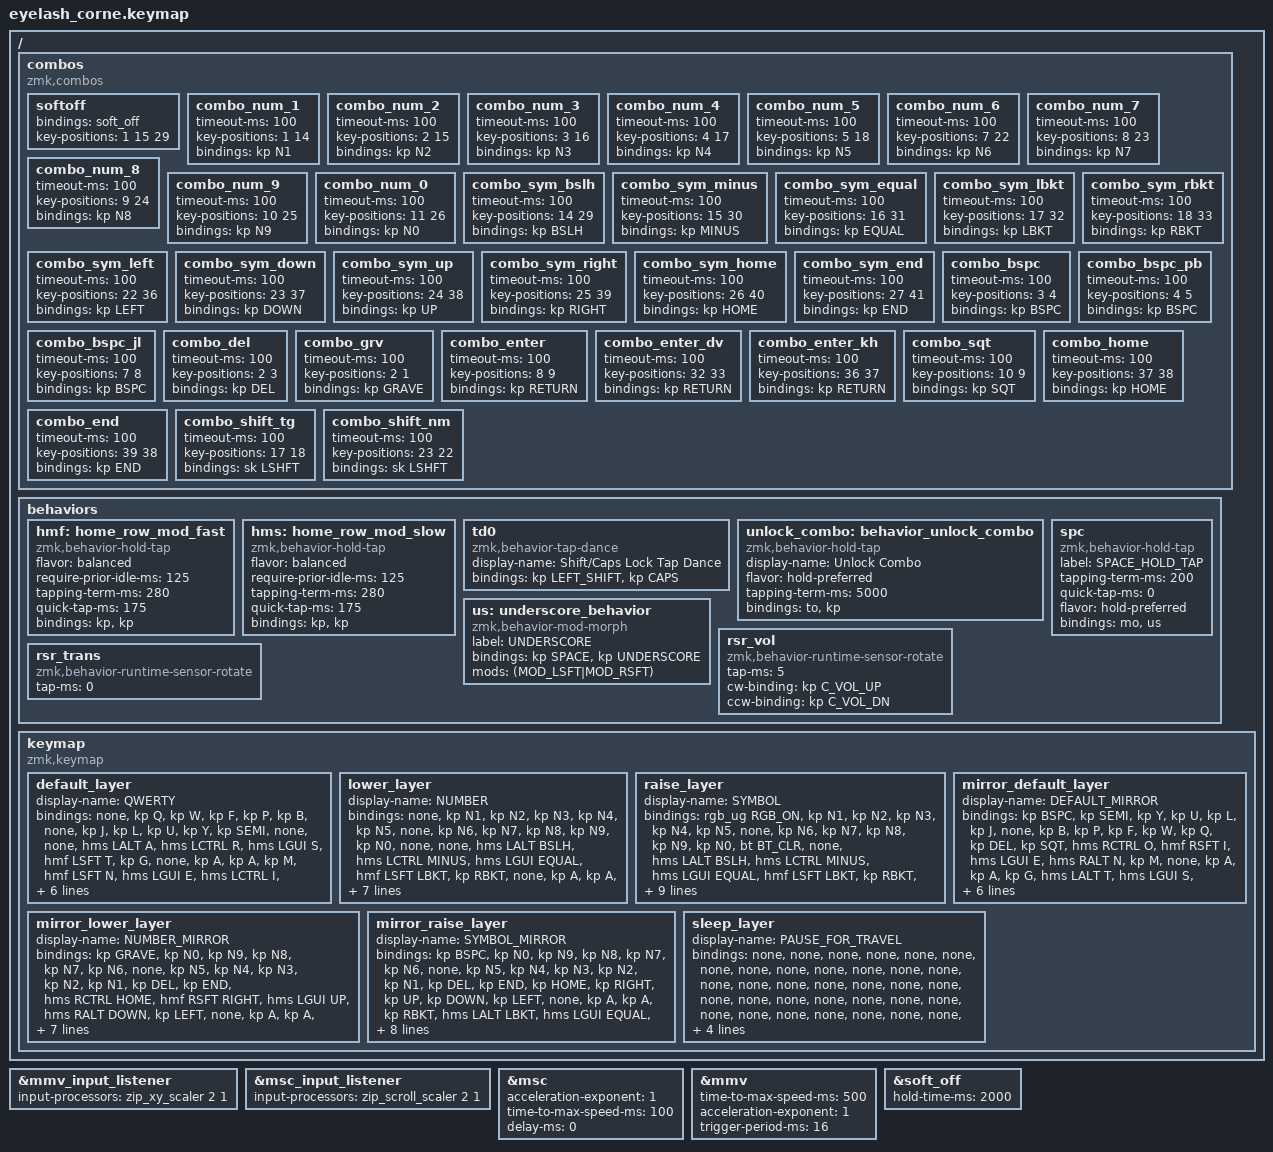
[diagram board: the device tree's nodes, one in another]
#define ZMK_POINTING_DEFAULT_MOVE_VAL 1200  // 600
#define ZMK_POINTING_DEFAULT_SCRL_VAL 25   // 10

#include <input/processors.dtsi>
#include <zephyr/dt-bindings/input/input-event-codes.h>
#include <behaviors.dtsi>
#include <behaviors/runtime-sensor-rotate.dtsi>
#include <dt-bindings/zmk/bt.h>
#include <dt-bindings/zmk/keys.h>
#include <dt-bindings/zmk/outputs.h>
#include <dt-bindings/zmk/pointing.h>
#include <dt-bindings/zmk/rgb.h>

&mmv_input_listener { input-processors = <&zip_xy_scaler 2 1>; };

&msc_input_listener { input-processors = <&zip_scroll_scaler 2 1>; };

&msc {
    acceleration-exponent = <1>;      // 0
    time-to-max-speed-ms = <100>;       // 300
    delay-ms = <0>;                   // 0
};

&mmv {
    time-to-max-speed-ms = <500>;
    acceleration-exponent = <1>;
    trigger-period-ms = <16>;
};

&soft_off { hold-time-ms = <2000>; };

/ {
    combos {
        compatible = "zmk,combos";
        softoff {
            bindings = <&soft_off>;
            key-positions = <1 15 29>;
        };

        // Top + middle row -> number (top key's number-layer binding)
        combo_num_1 { timeout-ms = <100>; key-positions = <1 14>;  bindings = <&kp N1>; };  // q + a
        combo_num_2 { timeout-ms = <100>; key-positions = <2 15>;  bindings = <&kp N2>; };  // w + r
        combo_num_3 { timeout-ms = <100>; key-positions = <3 16>;  bindings = <&kp N3>; };  // f + s
        combo_num_4 { timeout-ms = <100>; key-positions = <4 17>;  bindings = <&kp N4>; };  // p + t
        combo_num_5 { timeout-ms = <100>; key-positions = <5 18>;  bindings = <&kp N5>; };  // b + g
        combo_num_6 { timeout-ms = <100>; key-positions = <7 22>;  bindings = <&kp N6>; };  // j + m
        combo_num_7 { timeout-ms = <100>; key-positions = <8 23>;  bindings = <&kp N7>; };  // l + n
        combo_num_8 { timeout-ms = <100>; key-positions = <9 24>;  bindings = <&kp N8>; };  // u + e
        combo_num_9 { timeout-ms = <100>; key-positions = <10 25>; bindings = <&kp N9>; };  // y + i
        combo_num_0 { timeout-ms = <100>; key-positions = <11 26>; bindings = <&kp N0>; };  // ; + o

        // Middle + bottom row -> middle key's symbol-layer (alt) binding
        combo_sym_bslh  { timeout-ms = <100>; key-positions = <14 29>; bindings = <&kp BSLH>;  };  // a + z -> \
        combo_sym_minus { timeout-ms = <100>; key-positions = <15 30>; bindings = <&kp MINUS>; };  // r + x -> -
        combo_sym_equal { timeout-ms = <100>; key-positions = <16 31>; bindings = <&kp EQUAL>; };  // s + c -> =
        combo_sym_lbkt  { timeout-ms = <100>; key-positions = <17 32>; bindings = <&kp LBKT>;  };  // t + d -> [
        combo_sym_rbkt  { timeout-ms = <100>; key-positions = <18 33>; bindings = <&kp RBKT>;  };  // g + v -> ]
        combo_sym_left  { timeout-ms = <100>; key-positions = <22 36>; bindings = <&kp LEFT>;  };  // m + k -> left
        combo_sym_down  { timeout-ms = <100>; key-positions = <23 37>; bindings = <&kp DOWN>;  };  // n + h -> down
        combo_sym_up    { timeout-ms = <100>; key-positions = <24 38>; bindings = <&kp UP>;    };  // e + , -> up
        combo_sym_right { timeout-ms = <100>; key-positions = <25 39>; bindings = <&kp RIGHT>; };  // i + . -> right
        combo_sym_home  { timeout-ms = <100>; key-positions = <26 40>; bindings = <&kp HOME>;  };  // o + / -> home
        combo_sym_end   { timeout-ms = <100>; key-positions = <27 41>; bindings = <&kp END>;   };  // ' + caps_word -> end

        // Extra combos
        combo_bspc  { timeout-ms = <100>; key-positions = <3 4>;    bindings = <&kp BSPC>; };    // f + p -> backspace
        combo_bspc_pb { timeout-ms = <100>; key-positions = <4 5>;  bindings = <&kp BSPC>; };    // p + b -> backspace
        combo_bspc_jl { timeout-ms = <100>; key-positions = <7 8>; bindings = <&kp BSPC>; };  // j + l -> backspace
        combo_del   { timeout-ms = <100>; key-positions = <2 3>;    bindings = <&kp DEL>; };     // w + f -> delete
        combo_grv   { timeout-ms = <100>; key-positions = <2 1>;    bindings = <&kp GRAVE>; };   // w + q -> grave
        combo_enter { timeout-ms = <100>; key-positions = <8 9>;    bindings = <&kp RETURN>; };  // l + u -> enter
        combo_enter_dv { timeout-ms = <100>; key-positions = <32 33>; bindings = <&kp RETURN>; };  // d + v -> enter
        combo_enter_kh { timeout-ms = <100>; key-positions = <36 37>; bindings = <&kp RETURN>; };  // k + h -> enter
        combo_sqt   { timeout-ms = <100>; key-positions = <10 9>;   bindings = <&kp SQT>; };     // y + u -> '
        combo_home  { timeout-ms = <100>; key-positions = <37 38>;  bindings = <&kp HOME>; };    // h + , -> home
        combo_end   { timeout-ms = <100>; key-positions = <39 38>;  bindings = <&kp END>; };     // . + , -> end
        combo_shift_tg { timeout-ms = <100>; key-positions = <17 18>; bindings = <&sk LSHFT>; }; // t + g -> sticky shift
        combo_shift_nm { timeout-ms = <100>; key-positions = <23 22>; bindings = <&sk LSHFT>; }; // n + m -> sticky shift
    };
    behaviors {
        hmf: home_row_mod_fast {
            compatible = "zmk,behavior-hold-tap";
            #binding-cells = <2>;
            flavor = "balanced";
            require-prior-idle-ms = <125>;
            tapping-term-ms = <280>;
            quick-tap-ms = <175>;
            bindings = <&kp>, <&kp>;
        };
        hms: home_row_mod_slow {
            compatible = "zmk,behavior-hold-tap";
            #binding-cells = <2>;
            flavor = "balanced";
            require-prior-idle-ms = <125>;
            tapping-term-ms = <280>;
            quick-tap-ms = <175>;
            bindings = <&kp>, <&kp>;
        };
        td0: td0 {
            compatible = "zmk,behavior-tap-dance";
            display-name = "Shift/Caps Lock Tap Dance";
            #binding-cells = <0>;
            bindings = <&kp LEFT_SHIFT>, <&kp CAPS>;
        };

	unlock_combo: behavior_unlock_combo {
        compatible = "zmk,behavior-hold-tap";
	display-name = "Unlock Combo";
	#binding-cells = <2>;
        flavor = "hold-preferred";
        tapping-term-ms = <5000>; // 5-second hold
        bindings = <&to>, <&kp>;
    };

	spc: spc {
		compatible = "zmk,behavior-hold-tap";
    		label = "SPACE_HOLD_TAP";
  		#binding-cells = <2>;
		tapping-term-ms = <200>;
 		quick-tap-ms = <0>;
  		flavor = "hold-preferred";
 		bindings =<&mo>,  <&us>;
	};
	us: underscore_behavior {
            compatible = "zmk,behavior-mod-morph";
            label = "UNDERSCORE";
            #binding-cells = <0>;
	    bindings = <&kp SPACE>, <&kp UNDERSCORE>;
	    mods = <(MOD_LSFT|MOD_RSFT)>;
        };



        rsr_vol: rsr_vol {
            compatible = "zmk,behavior-runtime-sensor-rotate";
            #sensor-binding-cells = <0>;
            tap-ms = <5>;
            cw-binding = <&kp C_VOL_UP>;
            ccw-binding = <&kp C_VOL_DN>;
        };

        rsr_trans: rsr_trans {
            compatible = "zmk,behavior-runtime-sensor-rotate";
            #sensor-binding-cells = <0>;
            tap-ms = <0>;
        };
    };




    keymap {
        compatible = "zmk,keymap";


        default_layer {
            display-name = "QWERTY";
            bindings = <
&none &kp Q         &kp W        &kp F        &kp P        &kp B       &none               &kp J        &kp L        &kp U        &kp Y          &kp SEMI        &none
&none &hms LALT A  &hms LCTRL R  &hms LGUI S  &hmf LSFT T  &kp G       &none &kp A &kp A   &kp M        &hmf LSFT N  &hms LGUI E  &hms LCTRL I   &hms LALT O     &none
&none &kp Z         &kp X        &kp C        &kp D        &kp V       &none &kp A         &kp K        &kp H        &kp COMMA    &kp DOT        &kp FSLH        &none
                             &lt 2 ESC  &lt 1 TAB    &spc 3 &none                                           &spc 3 &none    &lt 2 ESC  &lt 1 TAB
            >;
            sensor-bindings = <&rsr_vol &rsr_trans>;
        };

        lower_layer {
            display-name = "NUMBER";
            bindings = <
&none &kp N1         &kp N2         &kp N3         &kp N4          &kp N5    &none              &kp N6    &kp N7       &kp N8       &kp N9       &kp N0           &none
&none &hms LALT BSLH &hms LCTRL MINUS &hms LGUI EQUAL &hmf LSFT LBKT &kp RBKT &none &kp A &kp A  &kp LEFT  &hmf RSFT DOWN  &hms LGUI UP  &hms LCTRL RIGHT  &hms RALT HOME  &none
&none &kp F2          &kp F3         &kp F4         &kp F5          &kp F6    &none &kp A        &kp F7    &kp F8       &kp F9       &kp F10      &kp F11          &none
                                &lt 2 ESC  &lt 1 TAB     &spc 3 &none                           &spc 3 &none   &lt 2 ESC  &lt 1 TAB  
            >;
            sensor-bindings = <&rsr_vol &rsr_trans>;
        };

        raise_layer {
            display-name = "SYMBOL";
            bindings = <
&rgb_ug RGB_ON        &kp N1          &kp N2       &kp N3       &kp N4       &kp N5       &none              &kp N6          &kp N7    &kp N8     &kp N9       &kp N0        &bt BT_CLR
&none  &hms LALT BSLH &hms LCTRL MINUS &hms LGUI EQUAL &hmf LSFT LBKT &kp RBKT  &none &kp A &kp A  &kp LEFT        &kp DOWN  &kp UP     &kp RIGHT    &kp HOME      &none
&rgb_ug RGB_OFF &kp GRAVE &kp C_VOL_DN &kp C_VOL_UP &kp C_BRI_DN &kp C_BRI_UP &none &kp A        &to 6           &kp PG_DN &kp PG_UP  &bt BT_SEL 0 &bt BT_SEL 1  &bt BT_SEL 2
			
                                             &lt 2 ESC  &lt 1 TAB   &spc 3 &none                           &spc 3 &none    &lt 2 ESC &lt 1 TAB  
            >;
            sensor-bindings = <&rsr_vol &rsr_trans>;
        };




        mirror_default_layer {
            display-name = "DEFAULT_MIRROR";
            bindings = <
&kp BSPC      &kp SEMI        &kp Y       &kp U       &kp L        &kp J       &none               &kp B        &kp P        &kp F        &kp W         &kp Q         &kp DEL
&kp SQT       &hms RCTRL O    &hmf RSFT I &hms LGUI E &hms RALT N  &kp M       &none &kp A &kp A   &kp G        &hms LALT T  &hms LGUI S  &hmf LSFT R   &hms LCTRL A  &kp BSPC
&caps_word    &kp FSLH        &kp DOT     &kp COMMA   &kp H        &kp K       &none &kp A         &kp V        &kp D        &kp C        &kp X         &kp Z         &mt LSHFT RETURN
                             &lt 5 TAB    &lt 3 SPACE    &lt 4 ESC                                           &lt 4 ESC    &lt 3 SPACE    &lt 5 TAB
    >;
            sensor-bindings = <&rsr_vol &rsr_trans>;
	};


        mirror_lower_layer {
            display-name = "NUMBER_MIRROR";
            bindings = <
&kp GRAVE  &kp N0          &kp N9       &kp N8       &kp N7       &kp N6    &none              &kp N5      &kp N4      &kp N3      &kp N2      &kp N1      &kp DEL
&kp END   &hms RCTRL HOME &hmf RSFT RIGHT  &hms LGUI UP  &hms RALT DOWN  &kp LEFT &none &kp A &kp A  &kp RBKT    &hms LALT LBKT &hms LGUI EQUAL &hmf LSFT MINUS &hms LCTRL BSLH &kp BSPC
&kp F12   &kp F11         &kp F10      &kp F9       &kp F8       &kp F7    &none &kp A        &kp F6      &kp F5      &kp F4      &kp F3      &kp F2       &kp F1
                             &lt 4 TAB    &lt 5 SPACE    &lt 5 ESC                          &lt 5 ESC    &lt 4 SPACE    &lt 4 TAB
    >;
			sensor-bindings = <&rsr_vol &rsr_trans>;
	};


        mirror_raise_layer {
            display-name = "SYMBOL_MIRROR";
            bindings =<
&kp BSPC       &kp N0        &kp N9       &kp N8       &kp N7       &kp N6       &none              &kp N5       &kp N4       &kp N3       &kp N2       &kp N1        &kp DEL
&kp END        &kp HOME      &kp RIGHT    &kp UP       &kp DOWN     &kp LEFT     &none &kp A &kp A  &kp RBKT    &hms LALT LBKT &hms LGUI EQUAL &hmf LSFT MINUS &hms LCTRL BSLH &kp BSPC
&bt BT_SEL 2   &bt BT_SEL 1  &bt BT_SEL 0 &kp PG_UP    &kp PG_DN    &trans       &none &kp A        &kp C_BRI_DN &kp C_BRI_UP &kp C_VOL_DN &kp C_VOL_UP &rgb_ug RGB_OFF &rgb_ug RGB_ON
                                            &lt 4 TAB    &lt 5 SPACE    &lt 5 ESC                       &lt 5 ESC    &lt 5 SPACE    &lt 4 TAB
    >;
			sensor-bindings = <&rsr_vol &rsr_trans>;
	};


 
	sleep_layer {
            display-name = "PAUSE_FOR_TRAVEL";
            bindings =<
&none  &none  &none  &none  &none  &none      &none                 &none           	  &none  &none  &none  &none  &none  
&none  &none  &none  &none  &none  &none      &none  &none  &none   &none           	  &none  &none  &none  &none  &none  
&none  &none  &none  &none  &none  &none      &none  &none          &unlock_combo 0 &none &none  &none  &none  &none  &none  
&none  &none  &none             &none  &none  &none  
    >;
			sensor-bindings = <&rsr_vol &rsr_trans>;
	};

};
};
